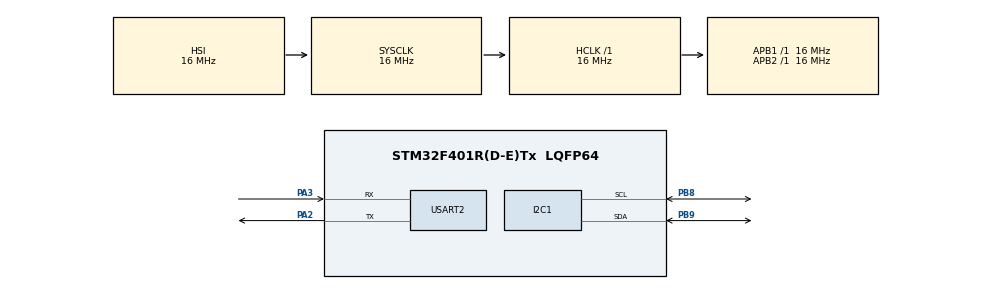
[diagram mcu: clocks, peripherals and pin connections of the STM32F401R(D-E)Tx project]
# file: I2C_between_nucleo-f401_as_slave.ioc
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Dma.I2C1_RX.0.Direction=DMA_PERIPH_TO_MEMORY
Dma.I2C1_RX.0.FIFOMode=DMA_FIFOMODE_DISABLE
Dma.I2C1_RX.0.Instance=DMA1_Stream0
Dma.I2C1_RX.0.MemDataAlignment=DMA_MDATAALIGN_BYTE
Dma.I2C1_RX.0.MemInc=DMA_MINC_ENABLE
Dma.I2C1_RX.0.Mode=DMA_NORMAL
Dma.I2C1_RX.0.PeriphDataAlignment=DMA_PDATAALIGN_BYTE
Dma.I2C1_RX.0.PeriphInc=DMA_PINC_DISABLE
Dma.I2C1_RX.0.Priority=DMA_PRIORITY_LOW
Dma.Request0=I2C1_RX
I2C1.OwnAddress=20
Mcu.Family=STM32F4
Mcu.Name=STM32F401R(D-E)Tx
Mcu.Package=LQFP64
NVIC.DMA1_Stream0_IRQn=true\:0\:0\:false\:false\:true\:false\:true\:true
NVIC.I2C1_ER_IRQn=true\:0\:0\:false\:false\:true\:true\:true\:true
NVIC.I2C1_EV_IRQn=true\:0\:0\:false\:false\:true\:true\:true\:true
NVIC.PriorityGroup=NVIC_PRIORITYGROUP_4
PA2.Mode=Asynchronous
PA2.Signal=USART2_TX
PA3.Mode=Asynchronous
PA3.Signal=USART2_RX
PB8.GPIO_Pu=GPIO_PULLUP
PB8.Mode=I2C
PB8.Signal=I2C1_SCL
PB9.GPIO_Pu=GPIO_PULLUP
PB9.Mode=I2C
PB9.Signal=I2C1_SDA
ProjectManager.HeapSize=0x200
ProjectManager.StackSize=0x400
ProjectManager.TargetToolchain=STM32CubeIDE
RCC.AHBFreq_Value=16000000
RCC.APB1Freq_Value=16000000
RCC.APB2Freq_Value=16000000
RCC.CortexFreq_Value=16000000
RCC.HSE_VALUE=25000000
RCC.HSI_VALUE=16000000
RCC.LSE_VALUE=32768
RCC.SYSCLKFreq_VALUE=16000000
RCC.VCOOutputFreq_Value=192000000
USART2.VirtualMode=VM_ASYNC
board=custom

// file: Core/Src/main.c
/* USER CODE BEGIN Header */
/**
  ******************************************************************************
  * @file           : main.c
  * @brief          : Main program body
  ******************************************************************************
  * @attention
  *
  * Copyright (c) 2025 STMicroelectronics.
  * All rights reserved.
  *
  * This software is licensed under terms that can be found in the LICENSE file
  * in the root directory of this software component.
  * If no LICENSE file comes with this software, it is provided AS-IS.
  *
  ******************************************************************************
  */
/* USER CODE END Header */
#include "main.h"

/* USER CODE BEGIN PD */
#define I2C1_SLAVE_ADDRESS 40 // 0d20 << 1
#define I2C_RECEIVE_MESSAGE_SIZE 32 // receiving message: "[I2C DATA] Hi, This is Master\r\n"
/* USER CODE END PD */

I2C_HandleTypeDef hi2c1;
DMA_HandleTypeDef hdma_i2c1_rx;

UART_HandleTypeDef huart2;

void SystemClock_Config(void);
static void MX_GPIO_Init(void);
static void MX_DMA_Init(void);
static void MX_I2C1_Init(void);
static void MX_USART2_UART_Init(void);

int main(void)
{

  /* USER CODE BEGIN 1 */
  HAL_StatusTypeDef i2c1_hal_status;
  uint8_t i2c1_receive_message [I2C_RECEIVE_MESSAGE_SIZE];
  uint8_t status_message_success[] = "[I2C slave] Success\r\n";
  uint8_t status_message_fail[] = "[I2C slave] Fail\r\n";
  /* USER CODE END 1 */

  /* MCU Configuration--------------------------------------------------------*/

  /* Reset of all peripherals, Initializes the Flash interface and the Systick. */
  HAL_Init();

  /* Configure the system clock */
  SystemClock_Config();

  /* Initialize all configured peripherals */
  MX_GPIO_Init();
  MX_DMA_Init();
  MX_I2C1_Init();
  MX_USART2_UART_Init();
  /* USER CODE BEGIN 2 */
  HAL_Delay(1000);

  //Receiving in Blocking mode
  i2c1_hal_status = HAL_I2C_Slave_Receive(&hi2c1, i2c1_receive_message, sizeof(i2c1_receive_message), HAL_MAX_DELAY);

  //Receiving in Interrupt mode
  // i2c1_hal_status = HAL_I2C_Slave_Receive_IT(&hi2c1 , (uint8_t *)i2c1_receive_message, I2C_RECEIVE_MESSAGE_SIZE);

  //Receiving in DMA mode
  // i2c1_hal_status = HAL_I2C_Slave_Receive_DMA(&hi2c1 , (uint8_t *)i2c1_receive_message, I2C_RECEIVE_MESSAGE_SIZE);

  if (i2c1_hal_status == HAL_OK)
  {
    HAL_UART_Transmit(&huart2, status_message_success, sizeof(status_message_success), 10);// Sending in normal mode
    HAL_UART_Transmit(&huart2, i2c1_receive_message, sizeof(i2c1_receive_message), 10);// Sending in normal mode
  }
  else
  {
    HAL_UART_Transmit(&huart2, status_message_fail, sizeof(status_message_fail), 10);// Sending in normal mode
  }
  /* USER CODE END 2 */

  /* Infinite loop */
  while (1)
  {

  }
}

void SystemClock_Config(void)
{
  RCC_OscInitTypeDef RCC_OscInitStruct = {0};
  RCC_ClkInitTypeDef RCC_ClkInitStruct = {0};

  /** Configure the main internal regulator output voltage
  */
  __HAL_RCC_PWR_CLK_ENABLE();
  __HAL_PWR_VOLTAGESCALING_CONFIG(PWR_REGULATOR_VOLTAGE_SCALE2);

  /** Initializes the RCC Oscillators according to the specified parameters
  * in the RCC_OscInitTypeDef structure.
  */
  RCC_OscInitStruct.OscillatorType = RCC_OSCILLATORTYPE_HSI;
  RCC_OscInitStruct.HSIState = RCC_HSI_ON;
  RCC_OscInitStruct.HSICalibrationValue = RCC_HSICALIBRATION_DEFAULT;
  RCC_OscInitStruct.PLL.PLLState = RCC_PLL_NONE;
  if (HAL_RCC_OscConfig(&RCC_OscInitStruct) != HAL_OK)
  {
    Error_Handler();
  }

  /** Initializes the CPU, AHB and APB buses clocks
  */
  RCC_ClkInitStruct.ClockType = RCC_CLOCKTYPE_HCLK|RCC_CLOCKTYPE_SYSCLK
                              |RCC_CLOCKTYPE_PCLK1|RCC_CLOCKTYPE_PCLK2;
  RCC_ClkInitStruct.SYSCLKSource = RCC_SYSCLKSOURCE_HSI;
  RCC_ClkInitStruct.AHBCLKDivider = RCC_SYSCLK_DIV1;
  RCC_ClkInitStruct.APB1CLKDivider = RCC_HCLK_DIV1;
  RCC_ClkInitStruct.APB2CLKDivider = RCC_HCLK_DIV1;

  if (HAL_RCC_ClockConfig(&RCC_ClkInitStruct, FLASH_LATENCY_0) != HAL_OK)
  {
    Error_Handler();
  }
}

static void MX_I2C1_Init(void)
{

  hi2c1.Instance = I2C1;
  hi2c1.Init.ClockSpeed = 100000;
  hi2c1.Init.DutyCycle = I2C_DUTYCYCLE_2;
  hi2c1.Init.OwnAddress1 = I2C1_SLAVE_ADDRESS;
  hi2c1.Init.AddressingMode = I2C_ADDRESSINGMODE_7BIT;
  hi2c1.Init.DualAddressMode = I2C_DUALADDRESS_DISABLE;
  hi2c1.Init.OwnAddress2 = 0;
  hi2c1.Init.GeneralCallMode = I2C_GENERALCALL_DISABLE;
  hi2c1.Init.NoStretchMode = I2C_NOSTRETCH_DISABLE;
  if (HAL_I2C_Init(&hi2c1) != HAL_OK)
  {
    Error_Handler();
  }

}

static void MX_USART2_UART_Init(void)
{

  huart2.Instance = USART2;
  huart2.Init.BaudRate = 115200;
  huart2.Init.WordLength = UART_WORDLENGTH_8B;
  huart2.Init.StopBits = UART_STOPBITS_1;
  huart2.Init.Parity = UART_PARITY_NONE;
  huart2.Init.Mode = UART_MODE_TX_RX;
  huart2.Init.HwFlowCtl = UART_HWCONTROL_NONE;
  huart2.Init.OverSampling = UART_OVERSAMPLING_16;
  if (HAL_UART_Init(&huart2) != HAL_OK)
  {
    Error_Handler();
  }

}

static void MX_DMA_Init(void)
{

  /* DMA controller clock enable */
  __HAL_RCC_DMA1_CLK_ENABLE();

  /* DMA interrupt init */
  /* DMA1_Stream0_IRQn interrupt configuration */
  HAL_NVIC_SetPriority(DMA1_Stream0_IRQn, 0, 0);
  HAL_NVIC_EnableIRQ(DMA1_Stream0_IRQn);

}

static void MX_GPIO_Init(void)
{

  /* GPIO Ports Clock Enable */
  __HAL_RCC_GPIOA_CLK_ENABLE();
  __HAL_RCC_GPIOB_CLK_ENABLE();

}

void Error_Handler(void)
{
  __disable_irq();
  while (1)
  {
  }
}
